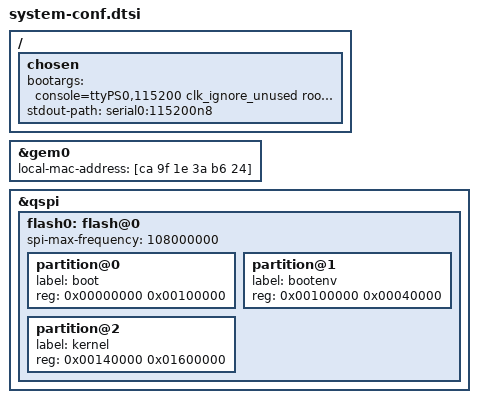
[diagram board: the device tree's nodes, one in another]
/*
 * CAUTION: This file is automatically generated by PetaLinux SDK.
 * DO NOT modify this file
 */


/ {
	chosen {
		bootargs = "console=ttyPS0,115200 clk_ignore_unused root=/dev/mmcblk1p2 rootfstype=ext4 rw rootwait earlyprintk";
		stdout-path = "serial0:115200n8";
	};
};

&gem0 {
	local-mac-address = [ca 9f 1e 3a b6 24];
};

&qspi {
	#address-cells = <1>;
	#size-cells = <0>;
	flash0: flash@0 {
		spi-max-frequency = <108000000>;
		partition@0 {
			label = "boot";
			reg = <0x00000000 0x00100000>;
		};
		partition@1 {
			label = "bootenv";
			reg = <0x00100000 0x00040000>;
		};
		partition@2 {
			label = "kernel";
			reg = <0x00140000 0x01600000>;
		};
	};
};

